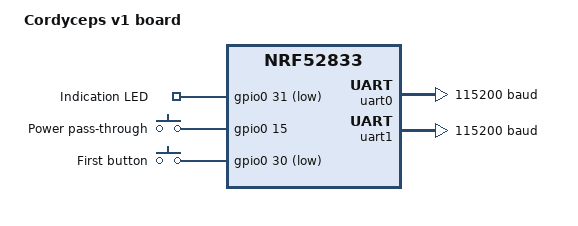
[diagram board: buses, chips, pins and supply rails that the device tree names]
/dts-v1/;
#include <nordic/nrf52833_qiaa.dtsi>
#include "board-pinctrl.dtsi"

/ {
	model = "Cordyceps v1 board";
	compatible = "aeremin,cordyceps";

	chosen {
		zephyr,console = &uart0;
		zephyr,sram = &sram0;
		zephyr,flash = &flash0;
	};

	power_control {
		compatible = "gpio-keys";
		led1: led1 {
			gpios = <&gpio0 31 (GPIO_ACTIVE_LOW | GPIO_PULL_UP)>;
			label = "Indication LED";
		};

		power_en: power_en {
			gpios = <&gpio0 15 (GPIO_ACTIVE_HIGH | GPIO_PULL_DOWN)>;
			label = "Power pass-through";
		};
	};

	buttons {
		compatible = "gpio-keys";
		button_sw1: button_sw1 {
			gpios = <&gpio0 30 (GPIO_PULL_UP | GPIO_ACTIVE_LOW)>;
			label = "First button";
		};
	};
};

&uart0 {
	status = "okay";
	compatible = "nordic,nrf-uart";
	current-speed = <115200>;
	pinctrl-0 = <&uart0_default>;
	pinctrl-names = "default";
};

&uart1 {
	status = "okay";
	compatible = "nordic,nrf-uart";
	current-speed = <115200>;
	pinctrl-0 = <&uart1_default>;
	pinctrl-names = "default";
};

&gpio0 {
	status = "okay";
};

&gpiote {
    status = "okay";
};

&flash0 {
	partitions {
		compatible = "fixed-partitions";
		#address-cells = <1>;
		#size-cells = <1>;

		boot_partition: partition@0 {
			label = "mcuboot";
			reg = <0x00000000 0xC000>;
		};
		slot0_partition: partition@c000 {
			label = "image-0";
			reg = <0x0000C000 0x32000>;
		};
		slot1_partition: partition@3e000 {
			label = "image-1";
			reg = <0x0003E000 0x32000>;
		};
		scratch_partition: partition@70000 {
			label = "image-scratch";
			reg = <0x00070000 0xA000>;
		};
		storage_partition: partition@7a000 {
			label = "storage";
			reg = <0x0007A000 0x00006000>;
		};
	};
};
